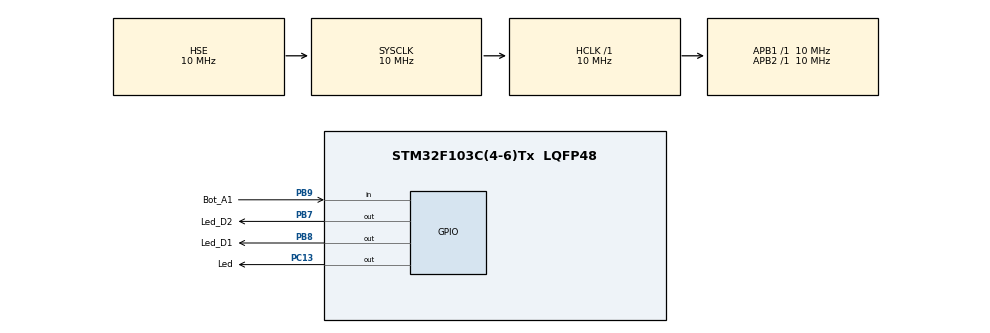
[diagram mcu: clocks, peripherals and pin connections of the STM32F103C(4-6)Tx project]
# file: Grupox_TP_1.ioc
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Mcu.Family=STM32F1
PC15-OSC32_OUT.Mode=LSE-External-Oscillator
PD1-OSC_OUT.Mode=HSE-External-Oscillator
PB9.GPIO_Label=Bot_A1
PC13-TAMPER-RTC.Signal=GPIO_Output
PD0-OSC_IN.Signal=RCC_OSC_IN
PC14-OSC32_IN.Signal=RCC_OSC32_IN
RCC.SYSCLKSource=RCC_SYSCLKSOURCE_HSE
ProjectManager.StackSize=0x400
PD1-OSC_OUT.Signal=RCC_OSC_OUT
PA13.Signal=SYS_JTMS-SWDIO
PB8.GPIO_Label=Led_D1
ProjectManager.TargetToolchain=STM32CubeIDE
RCC.HCLKFreq_Value=10000000
RCC.APB2TimFreq_Value=10000000
PC15-OSC32_OUT.Signal=RCC_OSC32_OUT
RCC.AHBFreq_Value=10000000
PD0-OSC_IN.Mode=HSE-External-Oscillator
RCC.HSE_VALUE=10000000
board=custom
PC13-TAMPER-RTC.GPIO_Label=Led
RCC.APB2Freq_Value=10000000
PC13-TAMPER-RTC.PinState=GPIO_PIN_SET
PC14-OSC32_IN.Mode=LSE-External-Oscillator
PB7.GPIO_ModeDefaultOutputPP=GPIO_MODE_OUTPUT_OD
PA14.Mode=Serial_Wire
PB8.PinState=GPIO_PIN_SET
PB7.Signal=GPIO_Output
PA13.Mode=Serial_Wire
Mcu.Name=STM32F103C(4-6)Tx
PB7.PinState=GPIO_PIN_SET
PB7.GPIO_Label=Led_D2
RCC.SYSCLKFreq_VALUE=10000000
Mcu.Package=LQFP48
PC13-TAMPER-RTC.GPIO_ModeDefaultOutputPP=GPIO_MODE_OUTPUT_OD
PB9.Signal=GPIO_Input
PA14.Signal=SYS_JTCK-SWCLK
ProjectManager.HeapSize=0x200
PB8.GPIO_ModeDefaultOutputPP=GPIO_MODE_OUTPUT_OD
NVIC.PriorityGroup=NVIC_PRIORITYGROUP_4
RCC.APB1TimFreq_Value=10000000
PB8.Signal=GPIO_Output
RCC.APB1Freq_Value=10000000

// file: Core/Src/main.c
/* USER CODE BEGIN Header */
/**
 ******************************************************************************
 * @file           : main.c
 * @brief          : Main program body
 ******************************************************************************
 * @attention
 *
 * <h2><center>&copy; Copyright (c) 2021 STMicroelectronics.
 * All rights reserved.</center></h2>
 *
 * This software component is licensed by ST under BSD 3-Clause license,
 * the "License"; You may not use this file except in compliance with the
 * License. You may obtain a copy of the License at:
 *                        opensource.org/licenses/BSD-3-Clause
 *
 ******************************************************************************
 */
/* USER CODE END Header */
#include "main.h"

/* USER CODE BEGIN Includes */
#include <App.h>
/* USER CODE END Includes */

void SystemClock_Config(void);
static void MX_GPIO_Init(void);

int main(void)
{

  /* MCU Configuration--------------------------------------------------------*/

  /* Reset of all peripherals, Initializes the Flash interface and the Systick. */
  HAL_Init();

  /* Configure the system clock */
  SystemClock_Config();

  /* Initialize all configured peripherals */
  MX_GPIO_Init();

  /* Infinite loop */
  /* USER CODE BEGIN WHILE */
	setup();
	while (1) {
		loop();
    /* USER CODE END WHILE */

	}
}

void SystemClock_Config(void)
{
  RCC_OscInitTypeDef RCC_OscInitStruct = {0};
  RCC_ClkInitTypeDef RCC_ClkInitStruct = {0};

  /** Initializes the RCC Oscillators according to the specified parameters
  * in the RCC_OscInitTypeDef structure.
  */
  RCC_OscInitStruct.OscillatorType = RCC_OSCILLATORTYPE_HSE;
  RCC_OscInitStruct.HSEState = RCC_HSE_ON;
  RCC_OscInitStruct.PLL.PLLState = RCC_PLL_NONE;
  if (HAL_RCC_OscConfig(&RCC_OscInitStruct) != HAL_OK)
  {
    Error_Handler();
  }
  /** Initializes the CPU, AHB and APB buses clocks
  */
  RCC_ClkInitStruct.ClockType = RCC_CLOCKTYPE_HCLK|RCC_CLOCKTYPE_SYSCLK
                              |RCC_CLOCKTYPE_PCLK1|RCC_CLOCKTYPE_PCLK2;
  RCC_ClkInitStruct.SYSCLKSource = RCC_SYSCLKSOURCE_HSE;
  RCC_ClkInitStruct.AHBCLKDivider = RCC_SYSCLK_DIV1;
  RCC_ClkInitStruct.APB1CLKDivider = RCC_HCLK_DIV1;
  RCC_ClkInitStruct.APB2CLKDivider = RCC_HCLK_DIV1;

  if (HAL_RCC_ClockConfig(&RCC_ClkInitStruct, FLASH_LATENCY_0) != HAL_OK)
  {
    Error_Handler();
  }
}

static void MX_GPIO_Init(void)
{
  GPIO_InitTypeDef GPIO_InitStruct = {0};

  /* GPIO Ports Clock Enable */
  __HAL_RCC_GPIOC_CLK_ENABLE();
  __HAL_RCC_GPIOD_CLK_ENABLE();
  __HAL_RCC_GPIOA_CLK_ENABLE();
  __HAL_RCC_GPIOB_CLK_ENABLE();

  /*Configure GPIO pin Output Level */
  HAL_GPIO_WritePin(Led_GPIO_Port, Led_Pin, GPIO_PIN_SET);

  /*Configure GPIO pin Output Level */
  HAL_GPIO_WritePin(GPIOB, Led_D2_Pin|Led_D1_Pin, GPIO_PIN_SET);

  /*Configure GPIO pin : Led_Pin */
  GPIO_InitStruct.Pin = Led_Pin;
  GPIO_InitStruct.Mode = GPIO_MODE_OUTPUT_OD;
  GPIO_InitStruct.Pull = GPIO_NOPULL;
  GPIO_InitStruct.Speed = GPIO_SPEED_FREQ_LOW;
  HAL_GPIO_Init(Led_GPIO_Port, &GPIO_InitStruct);

  /*Configure GPIO pins : Led_D2_Pin Led_D1_Pin */
  GPIO_InitStruct.Pin = Led_D2_Pin|Led_D1_Pin;
  GPIO_InitStruct.Mode = GPIO_MODE_OUTPUT_OD;
  GPIO_InitStruct.Pull = GPIO_NOPULL;
  GPIO_InitStruct.Speed = GPIO_SPEED_FREQ_LOW;
  HAL_GPIO_Init(GPIOB, &GPIO_InitStruct);

  /*Configure GPIO pin : Bot_A1_Pin */
  GPIO_InitStruct.Pin = Bot_A1_Pin;
  GPIO_InitStruct.Mode = GPIO_MODE_INPUT;
  GPIO_InitStruct.Pull = GPIO_NOPULL;
  HAL_GPIO_Init(Bot_A1_GPIO_Port, &GPIO_InitStruct);

}

void Error_Handler(void)
{
	__disable_irq();
	while (1) {
	}
}

/************************ (C) COPYRIGHT STMicroelectronics *****END OF FILE****/
